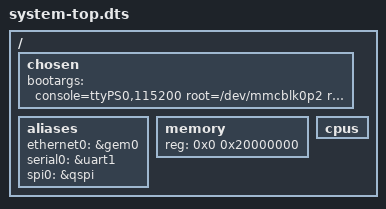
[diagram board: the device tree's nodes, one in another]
/*
 * CAUTION: This file is automatically generated by Xilinx.
 * Version:  
 * Today is: Sun Jul  9 20:39:39 2017
*/


/dts-v1/;
/include/ "zynq-7000.dtsi"
/include/ "pl.dtsi"
/include/ "pcw.dtsi"
/ {
	chosen {
		bootargs = "console=ttyPS0,115200 root=/dev/mmcblk0p2 rw earlyprintk rootfstype=ext4 rootwait uio_pdrv_genirq.of_id=generic-uio";
	};
	aliases {
		ethernet0 = &gem0;
		serial0 = &uart1;
		spi0 = &qspi;
	};
	memory {
		device_type = "memory";
		reg = <0x0 0x20000000>;
	};
	cpus {
	};
};
